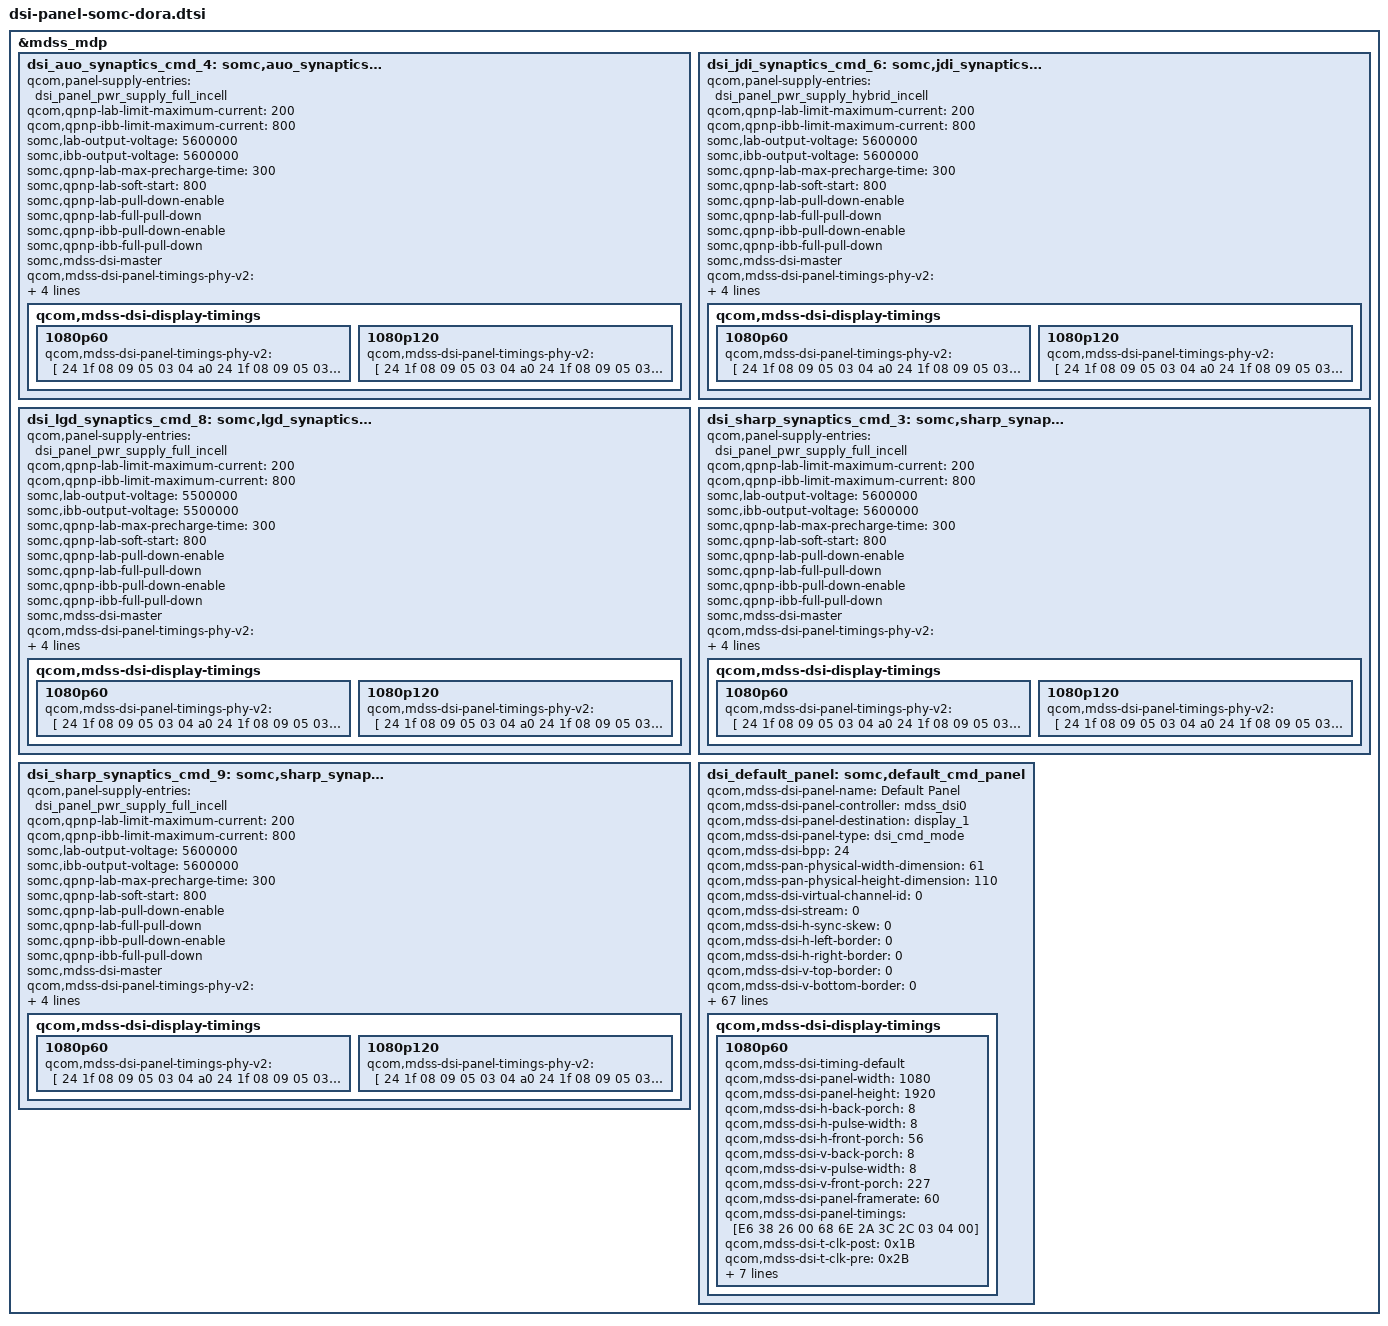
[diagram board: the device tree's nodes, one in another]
/* Copyright (c) 2013-2014, The Linux Foundation. All rights reserved.
 *
 * This program is free software; you can redistribute it and/or modify
 * it under the terms of the GNU General Public License version 2 and
 * only version 2 as published by the Free Software Foundation.
 *
 * This program is distributed in the hope that it will be useful,
 * but WITHOUT ANY WARRANTY; without even the implied warranty of
 * MERCHANTABILITY or FITNESS FOR A PARTICULAR PURPOSE.  See the
 * GNU General Public License for more details.
 */
/*
 * Copyright (C) 2015 Sony Mobile Communications Inc.
 *
 * This program is free software; you can redistribute it and/or modify
 * it under the terms of the GNU General Public License version 2, as
 * published by the Free Software Foundation.
 */
#include "dsi-panel-somc-synaptics-auo-1080p-cmd.dtsi"
#include "dsi-panel-somc-synaptics-jdi-1080p-cmd.dtsi"
#include "dsi-panel-somc-synaptics-lgd-1080p-cmd.dtsi"
#include "dsi-panel-somc-synaptics-sharp-1080p-cmd-ID3.dtsi"
#include "dsi-panel-somc-synaptics-sharp-1080p-cmd-ID9.dtsi"

&mdss_mdp {
	dsi_auo_synaptics_cmd_4: somc,auo_synaptics_cmd_4_panel {
		qcom,panel-supply-entries = <&dsi_panel_pwr_supply_full_incell>;
		qcom,qpnp-lab-limit-maximum-current = <200>;
		qcom,qpnp-ibb-limit-maximum-current = <800>;
		somc,lab-output-voltage = <5600000>;
		somc,ibb-output-voltage = <5600000>;
		somc,qpnp-lab-max-precharge-time = <300>;
		somc,qpnp-lab-soft-start = <800>;
		somc,qpnp-lab-pull-down-enable;
		somc,qpnp-lab-full-pull-down;
		somc,qpnp-ibb-pull-down-enable;
		somc,qpnp-ibb-full-pull-down;
		somc,mdss-dsi-master;
		qcom,mdss-dsi-panel-timings-phy-v2 = [
				24 1f 08 09 05 03 04 a0
				24 1f 08 09 05 03 04 a0
				24 1f 08 09 05 03 04 a0
				24 1f 08 09 05 03 04 a0
				24 1b 08 09 05 03 04 a0];
		qcom,dynamic-mode-switch-enabled;
		qcom,dynamic-mode-switch-type = "dynamic-resolution-switch-susres";
		qcom,mdss-dsi-display-timings {
			1080p60 {
				qcom,mdss-dsi-panel-timings-phy-v2 = [
						24 1f 08 09 05 03 04 a0
						24 1f 08 09 05 03 04 a0
						24 1f 08 09 05 03 04 a0
						24 1f 08 09 05 03 04 a0
						24 1b 08 09 05 03 04 a0];
			};

			1080p120 {
				qcom,mdss-dsi-panel-timings-phy-v2 = [
						24 1f 08 09 05 03 04 a0
						24 1f 08 09 05 03 04 a0
						24 1f 08 09 05 03 04 a0
						24 1f 08 09 05 03 04 a0
						24 1b 08 09 05 03 04 a0];
			};
		};
	};

	dsi_jdi_synaptics_cmd_6: somc,jdi_synaptics_cmd_6_panel {
		qcom,panel-supply-entries = <&dsi_panel_pwr_supply_hybrid_incell>;
		qcom,qpnp-lab-limit-maximum-current = <200>;
		qcom,qpnp-ibb-limit-maximum-current = <800>;
		somc,lab-output-voltage = <5600000>;
		somc,ibb-output-voltage = <5600000>;
		somc,qpnp-lab-max-precharge-time = <300>;
		somc,qpnp-lab-soft-start = <800>;
		somc,qpnp-lab-pull-down-enable;
		somc,qpnp-lab-full-pull-down;
		somc,qpnp-ibb-pull-down-enable;
		somc,qpnp-ibb-full-pull-down;
		somc,mdss-dsi-master;
		qcom,mdss-dsi-panel-timings-phy-v2 = [
				24 1f 08 09 05 03 04 a0
				24 1f 08 09 05 03 04 a0
				24 1f 08 09 05 03 04 a0
				24 1f 08 09 05 03 04 a0
				24 1b 08 09 05 03 04 a0];
		qcom,dynamic-mode-switch-enabled;
		qcom,dynamic-mode-switch-type = "dynamic-resolution-switch-susres";
		qcom,mdss-dsi-display-timings {
			1080p60 {
				qcom,mdss-dsi-panel-timings-phy-v2 = [
						24 1f 08 09 05 03 04 a0
						24 1f 08 09 05 03 04 a0
						24 1f 08 09 05 03 04 a0
						24 1f 08 09 05 03 04 a0
						24 1b 08 09 05 03 04 a0];
			};

			1080p120 {
				qcom,mdss-dsi-panel-timings-phy-v2 = [
						24 1f 08 09 05 03 04 a0
						24 1f 08 09 05 03 04 a0
						24 1f 08 09 05 03 04 a0
						24 1f 08 09 05 03 04 a0
						24 1b 08 09 05 03 04 a0];
			};
		};
	};

	dsi_lgd_synaptics_cmd_8: somc,lgd_synaptics_cmd_8_panel {
		qcom,panel-supply-entries = <&dsi_panel_pwr_supply_full_incell>;
		qcom,qpnp-lab-limit-maximum-current = <200>;
		qcom,qpnp-ibb-limit-maximum-current = <800>;
		somc,lab-output-voltage = <5500000>;
		somc,ibb-output-voltage = <5500000>;
		somc,qpnp-lab-max-precharge-time = <300>;
		somc,qpnp-lab-soft-start = <800>;
		somc,qpnp-lab-pull-down-enable;
		somc,qpnp-lab-full-pull-down;
		somc,qpnp-ibb-pull-down-enable;
		somc,qpnp-ibb-full-pull-down;
		somc,mdss-dsi-master;
		qcom,mdss-dsi-panel-timings-phy-v2 = [
				24 1f 08 09 05 03 04 a0
				24 1f 08 09 05 03 04 a0
				24 1f 08 09 05 03 04 a0
				24 1f 08 09 05 03 04 a0
				24 1b 08 09 05 03 04 a0];
		qcom,dynamic-mode-switch-enabled;
		qcom,dynamic-mode-switch-type = "dynamic-resolution-switch-susres";
		qcom,mdss-dsi-display-timings {
			1080p60 {
				qcom,mdss-dsi-panel-timings-phy-v2 = [
						24 1f 08 09 05 03 04 a0
						24 1f 08 09 05 03 04 a0
						24 1f 08 09 05 03 04 a0
						24 1f 08 09 05 03 04 a0
						24 1b 08 09 05 03 04 a0];
			};

			1080p120 {
				qcom,mdss-dsi-panel-timings-phy-v2 = [
						24 1f 08 09 05 03 04 a0
						24 1f 08 09 05 03 04 a0
						24 1f 08 09 05 03 04 a0
						24 1f 08 09 05 03 04 a0
						24 1b 08 09 05 03 04 a0];
			};
		};
	};

	dsi_sharp_synaptics_cmd_3: somc,sharp_synaptics_cmd_3_panel {
		qcom,panel-supply-entries = <&dsi_panel_pwr_supply_full_incell>;
		qcom,qpnp-lab-limit-maximum-current = <200>;
		qcom,qpnp-ibb-limit-maximum-current = <800>;
		somc,lab-output-voltage = <5600000>;
		somc,ibb-output-voltage = <5600000>;
		somc,qpnp-lab-max-precharge-time = <300>;
		somc,qpnp-lab-soft-start = <800>;
		somc,qpnp-lab-pull-down-enable;
		somc,qpnp-lab-full-pull-down;
		somc,qpnp-ibb-pull-down-enable;
		somc,qpnp-ibb-full-pull-down;
		somc,mdss-dsi-master;
		qcom,mdss-dsi-panel-timings-phy-v2 = [
				24 1f 08 09 05 03 04 a0
				24 1f 08 09 05 03 04 a0
				24 1f 08 09 05 03 04 a0
				24 1f 08 09 05 03 04 a0
				24 1b 08 09 05 03 04 a0];
		qcom,dynamic-mode-switch-enabled;
		qcom,dynamic-mode-switch-type = "dynamic-resolution-switch-susres";
		qcom,mdss-dsi-display-timings {
			1080p60 {
				qcom,mdss-dsi-panel-timings-phy-v2 = [
						24 1f 08 09 05 03 04 a0
						24 1f 08 09 05 03 04 a0
						24 1f 08 09 05 03 04 a0
						24 1f 08 09 05 03 04 a0
						24 1b 08 09 05 03 04 a0];
			};

			1080p120 {
				qcom,mdss-dsi-panel-timings-phy-v2 = [
						24 1f 08 09 05 03 04 a0
						24 1f 08 09 05 03 04 a0
						24 1f 08 09 05 03 04 a0
						24 1f 08 09 05 03 04 a0
						24 1b 08 09 05 03 04 a0];
			};
		};
	};

	dsi_sharp_synaptics_cmd_9: somc,sharp_synaptics_cmd_9_panel {
		qcom,panel-supply-entries = <&dsi_panel_pwr_supply_full_incell>;
		qcom,qpnp-lab-limit-maximum-current = <200>;
		qcom,qpnp-ibb-limit-maximum-current = <800>;
		somc,lab-output-voltage = <5600000>;
		somc,ibb-output-voltage = <5600000>;
		somc,qpnp-lab-max-precharge-time = <300>;
		somc,qpnp-lab-soft-start = <800>;
		somc,qpnp-lab-pull-down-enable;
		somc,qpnp-lab-full-pull-down;
		somc,qpnp-ibb-pull-down-enable;
		somc,qpnp-ibb-full-pull-down;
		somc,mdss-dsi-master;
		qcom,mdss-dsi-panel-timings-phy-v2 = [
				24 1f 08 09 05 03 04 a0
				24 1f 08 09 05 03 04 a0
				24 1f 08 09 05 03 04 a0
				24 1f 08 09 05 03 04 a0
				24 1b 08 09 05 03 04 a0];
		qcom,dynamic-mode-switch-enabled;
		qcom,dynamic-mode-switch-type = "dynamic-resolution-switch-susres";
		qcom,mdss-dsi-display-timings {
			1080p60 {
				qcom,mdss-dsi-panel-timings-phy-v2 = [
						24 1f 08 09 05 03 04 a0
						24 1f 08 09 05 03 04 a0
						24 1f 08 09 05 03 04 a0
						24 1f 08 09 05 03 04 a0
						24 1b 08 09 05 03 04 a0];
			};

			1080p120 {
				qcom,mdss-dsi-panel-timings-phy-v2 = [
						24 1f 08 09 05 03 04 a0
						24 1f 08 09 05 03 04 a0
						24 1f 08 09 05 03 04 a0
						24 1f 08 09 05 03 04 a0
						24 1b 08 09 05 03 04 a0];
			};
		};
	};

	dsi_default_panel: somc,default_cmd_panel {
		qcom,mdss-dsi-panel-name = "Default Panel";
		qcom,mdss-dsi-panel-controller = <&mdss_dsi0>;
		qcom,mdss-dsi-panel-destination = "display_1";
		qcom,mdss-dsi-panel-type = "dsi_cmd_mode";
		qcom,mdss-dsi-bpp = <24>;
		qcom,mdss-pan-physical-width-dimension = <61>;
		qcom,mdss-pan-physical-height-dimension = <110>;
		qcom,mdss-dsi-virtual-channel-id = <0>;
		qcom,mdss-dsi-stream = <0>;
		qcom,mdss-dsi-h-sync-skew = <0>;
		qcom,mdss-dsi-h-left-border = <0>;
		qcom,mdss-dsi-h-right-border = <0>;
		qcom,mdss-dsi-v-top-border = <0>;
		qcom,mdss-dsi-v-bottom-border = <0>;
		qcom,mdss-dsi-underflow-color = <0x0>;
		qcom,mdss-dsi-border-color = <0>;
		qcom,mdss-dsi-h-sync-pulse = <1>;
		qcom,mdss-dsi-traffic-mode = "non_burst_sync_event";
		qcom,mdss-dsi-bllp-eof-power-mode;
		qcom,mdss-dsi-bllp-power-mode;
		qcom,mdss-dsi-dma-trigger = "trigger_sw";
		qcom,mdss-dsi-mdp-trigger = "none";
		qcom,mdss-dsi-tx-eot-append;
		qcom,mdss-dsi-off-command = [
				39 01 00 00 14 00 01 28
				39 01 00 00 50 00 01 10];
		qcom,mdss-dsi-off-command-state = "dsi_hs_mode";
		qcom,mdss-dsi-te-pin-select = <1>;
		qcom,mdss-dsi-wr-mem-start = <0x2c>;
		qcom,mdss-dsi-wr-mem-continue = <0x3c>;
		qcom,mdss-dsi-te-dcs-command = <1>;
		qcom,mdss-dsi-te-check-enable;
		qcom,mdss-dsi-te-using-te-pin;
		qcom,mdss-dsi-lane-0-state;
		qcom,mdss-dsi-lane-1-state;
		qcom,mdss-dsi-lane-2-state;
		qcom,mdss-dsi-lane-3-state;
		qcom,panel-supply-entries = <&dsi_panel_pwr_supply_hybrid_incell>;
		qcom,mdss-dsi-lp11-init;
		qcom,mdss-dsi-bl-min-level = <1>;
		qcom,mdss-dsi-bl-max-level = <4095>;
		qcom,mdss-brightness-max-level = <255>;
		qcom,mdss-dsi-bl-pmic-control-type = "bl_ctrl_wled";
		qcom,qpnp-lab-limit-maximum-current = <200>;
		qcom,qpnp-ibb-limit-maximum-current = <800>;

		somc,qpnp-lab-max-precharge-time = <300>;
		somc,qpnp-lab-soft-start = <800>;
		somc,qpnp-lab-pull-down-enable;
		somc,qpnp-lab-full-pull-down;
		somc,qpnp-ibb-pull-down-enable;
		somc,qpnp-ibb-full-pull-down;
		somc,lcd-id = <0>;
		somc,lcd-id-adc = <0 0x7fffffff>;
		somc,mdss-dsi-master;
		somc,pw-on-rst-seq = <0 10>, <1 16>, <0 7>, <1 16>;
		somc,pw-off-rst-b-seq = <0 11>;
		somc,pw-wait-after-on-vdd = <0>;
		somc,pw-wait-after-on-vddio = <1>;
		somc,pw-wait-after-on-vsp = <1>;
		somc,pw-wait-after-on-vsn = <0>;
		somc,pw-wait-after-off-vdd = <0>;
		somc,pw-wait-after-off-vddio = <1>;
		somc,pw-wait-after-off-vsp = <10>;
		somc,pw-wait-after-off-vsn = <10>;
		somc,pw-wait-after-on-touch-avdd = <0>;
		somc,pw-wait-after-on-touch-vddio = <0>;
		somc,pw-wait-after-on-touch-reset = <0>;
		somc,pw-wait-after-on-touch-reset-first = <90>;
		somc,pw-wait-after-on-touch-int-n = <10>;
		somc,pw-wait-after-off-touch-avdd = <0>;
		somc,pw-wait-after-off-touch-vddio = <0>;
		somc,pw-wait-after-off-touch-reset = <5>;
		somc,pw-wait-after-off-touch-int-n = <0>;
		somc,pw-down-period = <300>;
		somc,lab-output-voltage = <5600000>;
		somc,ibb-output-voltage = <5600000>;

		qcom,mdss-dsi-panel-timings-phy-v2 = [
				24 1f 08 09 05 03 04 a0
				24 1f 08 09 05 03 04 a0
				24 1f 08 09 05 03 04 a0
				24 1f 08 09 05 03 04 a0
				24 1b 08 09 05 03 04 a0];

		somc,ewu-wait-after-touch-reset = <40>;

		qcom,mdss-dsi-display-timings {
			1080p60 {
				qcom,mdss-dsi-timing-default;
				qcom,mdss-dsi-panel-width = <1080>;
				qcom,mdss-dsi-panel-height = <1920>;
				qcom,mdss-dsi-h-back-porch = <8>;
				qcom,mdss-dsi-h-pulse-width = <8>;
				qcom,mdss-dsi-h-front-porch = <56>;
				qcom,mdss-dsi-v-back-porch = <8>;
				qcom,mdss-dsi-v-pulse-width = <8>;
				qcom,mdss-dsi-v-front-porch = <227>;
				qcom,mdss-dsi-panel-framerate = <60>;
				qcom,mdss-dsi-panel-timings = [E6 38 26 00 68 6E 2A 3C 2C 03 04 00];
				qcom,mdss-dsi-t-clk-post = <0x1B>;
				qcom,mdss-dsi-t-clk-pre = <0x2B>;
				qcom,mdss-dsi-panel-timings-phy-v2 = [
						24 1f 08 09 05 03 04 a0
						24 1f 08 09 05 03 04 a0
						24 1f 08 09 05 03 04 a0
						24 1f 08 09 05 03 04 a0
						24 1b 08 09 05 03 04 a0];
				qcom,mdss-dsi-on-command = [
						39 01 00 00 00 00 02 36 00
						39 01 00 00 00 00 02 3A 77
						39 01 00 00 00 00 05 2A 00 00 04 37
						39 01 00 00 00 00 05 2B 00 00 07 7F
						39 01 00 00 78 00 01 11];
				qcom,mdss-dsi-post-panel-on-command = [
						39 01 00 00 00 00 01 29];
				qcom,mdss-dsi-on-command-state = "dsi_lp_mode";
			};
		};
	};
};
